# STM32H5F5xx register map
File version: 1.0
Registers are 32-bit, read-write, reset 0x0 unless marked. A register's access mark holds for its fields unless they carry their own. Offsets are from the block's base; [hi:lo] are bit positions; {n}, {i} and the like mark numbered series; 'fields as' and 'values as' point back to an identical list.

## ETH — Ethernet MAC
Base 0x40028000
Same registers: ETH_S 0x50028000
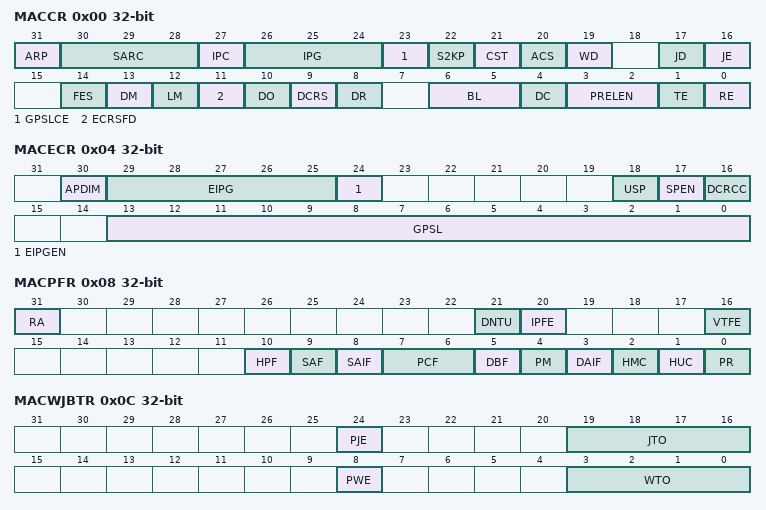
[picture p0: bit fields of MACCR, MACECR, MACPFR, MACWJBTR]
0x00 MACCR
  [31] ARP, [30:28] SARC, [27] IPC, [26:24] IPG, [23] GPSLCE, [22] S2KP, [21] CST, [20] ACS, [19] WD, [17] JD, [16] JE, [14] FES, [13] DM, [12] LM, [11] ECRSFD, [10] DO, [9] DCRS, [8] DR, [6:5] BL, [4] DC, [3:2] PRELEN, [1] TE, [0] RE
0x04 MACECR
  [30] APDIM, [29:25] EIPG, [24] EIPGEN, [18] USP, [17] SPEN, [16] DCRCC, [13:0] GPSL
0x08 MACPFR
  [31] RA, [21] DNTU, [20] IPFE, [16] VTFE, [10] HPF, [9] SAF, [8] SAIF, [7:6] PCF, [5] DBF, [4] PM, [3] DAIF, [2] HMC, [1] HUC, [0] PR
0x0C MACWJBTR
  [24] PJE, [19:16] JTO, [8] PWE, [3:0] WTO
0x10 MACHT0R
0x14 MACHT1R
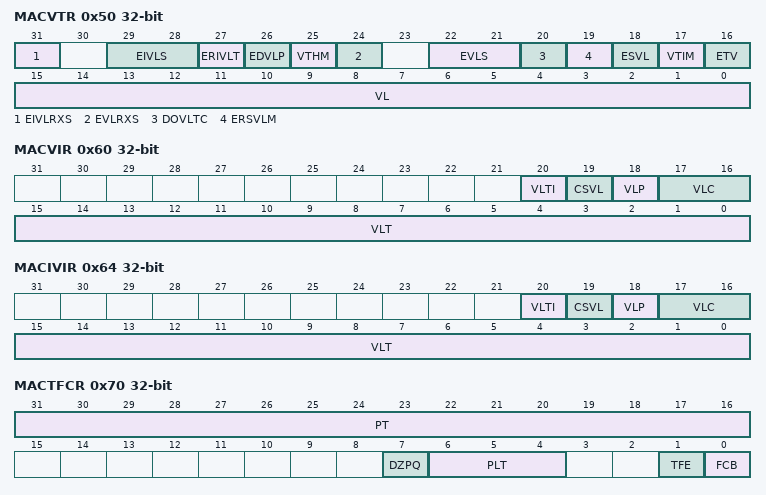
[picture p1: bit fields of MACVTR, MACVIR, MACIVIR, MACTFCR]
0x50 MACVTR
  [31] EIVLRXS, [29:28] EIVLS, [27] ERIVLT, [26] EDVLP, [25] VTHM, [24] EVLRXS, [22:21] EVLS, [20] DOVLTC, [19] ERSVLM, [18] ESVL, [17] VTIM, [16] ETV, [15:0] VL
0x58 MACVHTR
  [15:0] VLHT
0x60 MACVIR
  [20] VLTI, [19] CSVL, [18] VLP, [17:16] VLC, [15:0] VLT
0x64 MACIVIR
  [20] VLTI, [19] CSVL, [18] VLP, [17:16] VLC, [15:0] VLT
0x70 MACTFCR
  [31:16] PT, [7] DZPQ, [6:4] PLT, [1] TFE, [0] FCB
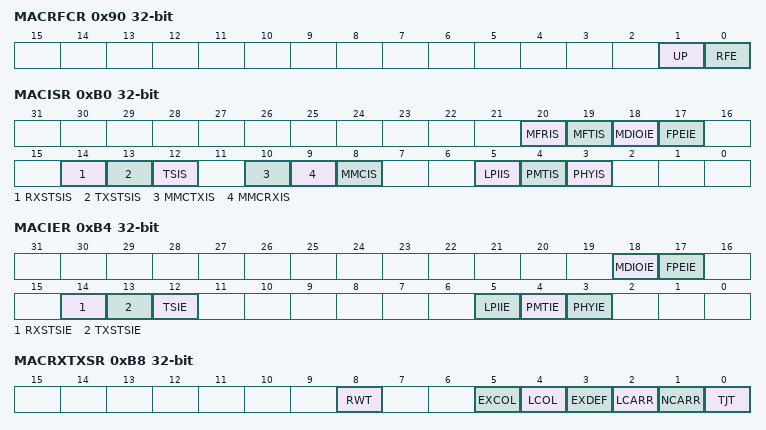
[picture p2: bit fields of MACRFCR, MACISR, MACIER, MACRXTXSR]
0x90 MACRFCR
  [1] UP, [0] RFE
0xB0 MACISR
  [20] MFRIS, [19] MFTIS, [18] MDIOIE, [17] FPEIE, [14] RXSTSIS, [13] TXSTSIS, [12] TSIS, [10] MMCTXIS, [9] MMCRXIS, [8] MMCIS, [5] LPIIS, [4] PMTIS, [3] PHYIS
0xB4 MACIER
  [18] MDIOIE, [17] FPEIE, [14] RXSTSIE, [13] TXSTSIE, [12] TSIE, [5] LPIIE, [4] PMTIE, [3] PHYIE
0xB8 MACRXTXSR
  [8] RWT, [5] EXCOL, [4] LCOL, [3] EXDEF, [2] LCARR, [1] NCARR, [0] TJT
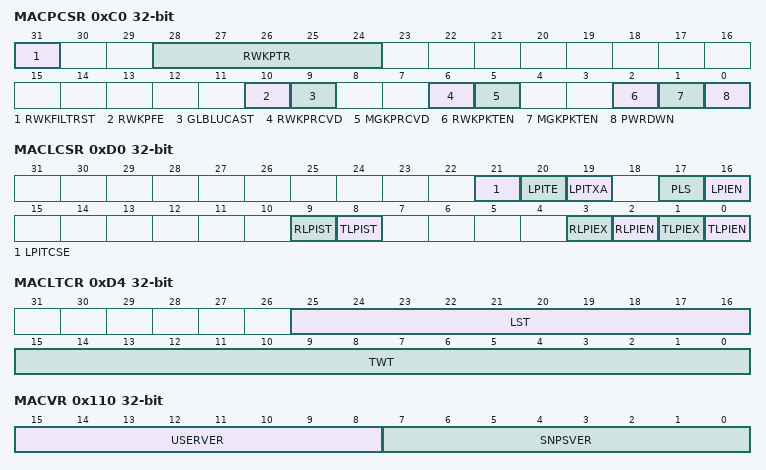
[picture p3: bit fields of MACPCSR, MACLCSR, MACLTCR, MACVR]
0xC0 MACPCSR
  [31] RWKFILTRST, [28:24] RWKPTR, [10] RWKPFE, [9] GLBLUCAST, [6] RWKPRCVD, [5] MGKPRCVD, [2] RWKPKTEN, [1] MGKPKTEN, [0] PWRDWN
0xC4 MACRWKPFR
0xD0 MACLCSR
  [21] LPITCSE, [20] LPITE, [19] LPITXA, [17] PLS, [16] LPIEN, [9] RLPIST, [8] TLPIST, [3] RLPIEX, [2] RLPIEN, [1] TLPIEX, [0] TLPIEN
0xD4 MACLTCR
  [25:16] LST, [15:0] TWT
0xD8 MACLETR
  [19:0] LPIET
0xDC MAC1USTCR
  [11:0] TIC1USCNTR
0x110 MACVR
  [15:8] USERVER, [7:0] SNPSVER
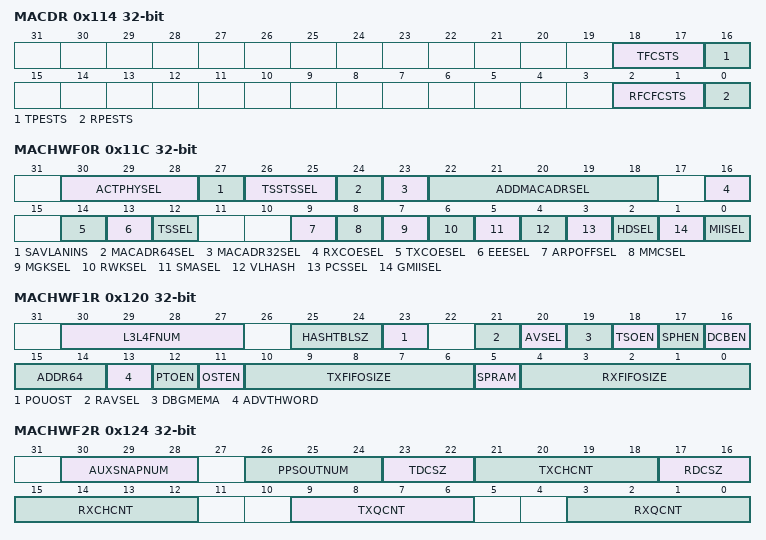
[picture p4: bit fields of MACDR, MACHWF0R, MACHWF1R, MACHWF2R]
0x114 MACDR
  [18:17] TFCSTS, [16] TPESTS, [2:1] RFCFCSTS, [0] RPESTS
0x11C MACHWF0R
  [30:28] ACTPHYSEL, [27] SAVLANINS, [26:25] TSSTSSEL, [24] MACADR64SEL, [23] MACADR32SEL, [22:18] ADDMACADRSEL, [16] RXCOESEL, [14] TXCOESEL, [13] EEESEL, [12] TSSEL, [9] ARPOFFSEL, [8] MMCSEL, [7] MGKSEL, [6] RWKSEL, [5] SMASEL, [4] VLHASH, [3] PCSSEL, [2] HDSEL, [1] GMIISEL, [0] MIISEL
0x120 MACHWF1R
  [30:27] L3L4FNUM, [25:24] HASHTBLSZ, [23] POUOST, [21] RAVSEL, [20] AVSEL, [19] DBGMEMA, [18] TSOEN, [17] SPHEN, [16] DCBEN, [15:14] ADDR64, [13] ADVTHWORD, [12] PTOEN, [11] OSTEN, [10:6] TXFIFOSIZE, [5] SPRAM, [4:0] RXFIFOSIZE
0x124 MACHWF2R
  [30:28] AUXSNAPNUM, [26:24] PPSOUTNUM, [23:22] TDCSZ, [21:18] TXCHCNT, [17:16] RDCSZ, [15:12] RXCHCNT, [9:6] TXQCNT, [3:0] RXQCNT
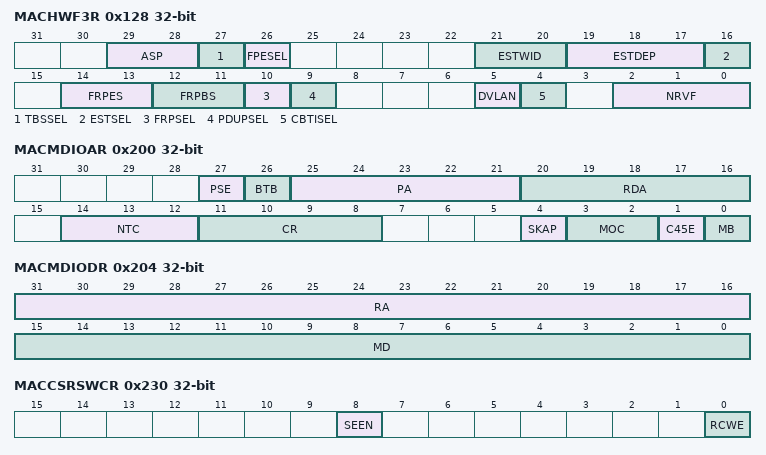
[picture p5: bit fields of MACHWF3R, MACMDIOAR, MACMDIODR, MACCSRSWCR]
0x128 MACHWF3R
  [29:28] ASP, [27] TBSSEL, [26] FPESEL, [21:20] ESTWID, [19:17] ESTDEP, [16] ESTSEL, [14:13] FRPES, [12:11] FRPBS, [10] FRPSEL, [9] PDUPSEL, [5] DVLAN, [4] CBTISEL, [2:0] NRVF
0x200 MACMDIOAR
  [27] PSE, [26] BTB, [25:21] PA, [20:16] RDA, [14:12] NTC, [11:8] CR, [4] SKAP, [3:2] MOC, [1] C45E, [0] MB
0x204 MACMDIODR
  [31:16] RA, [15:0] MD
0x210 MACARPAR
  [31:0] ARPPA
0x230 MACCSRSWCR
  [8] SEEN, [0] RCWE
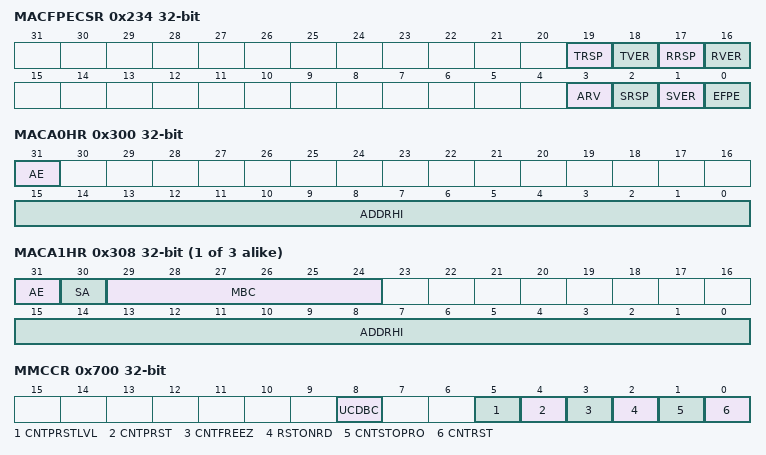
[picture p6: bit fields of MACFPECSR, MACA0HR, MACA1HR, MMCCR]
0x234 MACFPECSR
  [19] TRSP, [18] TVER, [17] RRSP, [16] RVER, [3] ARV, [2] SRSP, [1] SVER, [0] EFPE
0x240 MACPRSTIMR
  [31:0] MPTN
0x244 MACPRSTIMUR
  [31:0] MPTU
0x300 MACA0HR
  [31] AE, [15:0] ADDRHI
{0x304+8i} MACA{i}LR (i=0..3)
  [31:0] ADDRLO
{0x300+8i} MACA{i}HR (i=1..3)
  [31] AE, [30] SA, [29:24] MBC, [15:0] ADDRHI
0x700 MMCCR
  [8] UCDBC, [5] CNTPRSTLVL, [4] CNTPRST, [3] CNTFREEZ, [2] RSTONRD, [1] CNTSTOPRO, [0] CNTRST
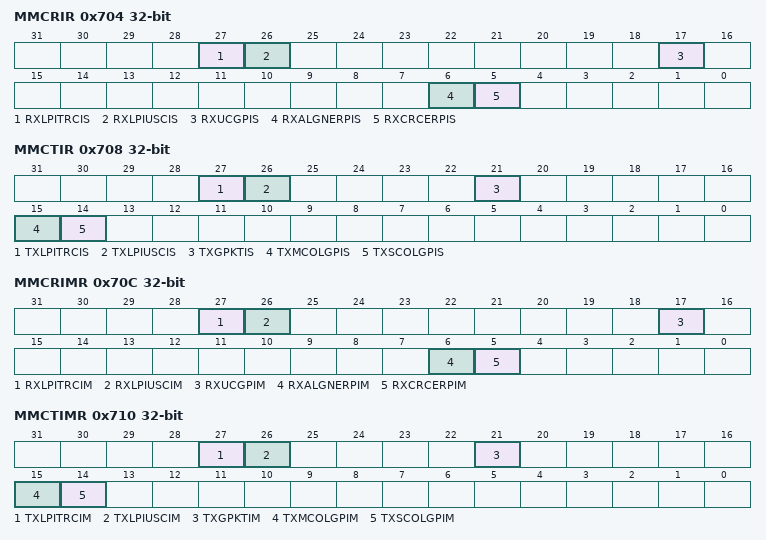
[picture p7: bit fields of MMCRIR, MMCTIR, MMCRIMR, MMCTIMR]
0x704 MMCRIR
  [27] RXLPITRCIS, [26] RXLPIUSCIS, [17] RXUCGPIS, [6] RXALGNERPIS, [5] RXCRCERPIS
0x708 MMCTIR
  [27] TXLPITRCIS, [26] TXLPIUSCIS, [21] TXGPKTIS, [15] TXMCOLGPIS, [14] TXSCOLGPIS
0x70C MMCRIMR
  [27] RXLPITRCIM, [26] RXLPIUSCIM, [17] RXUCGPIM, [6] RXALGNERPIM, [5] RXCRCERPIM
0x710 MMCTIMR
  [27] TXLPITRCIM, [26] TXLPIUSCIM, [21] TXGPKTIM, [15] TXMCOLGPIM, [14] TXSCOLGPIM
0x74C MMCTSCGPR
0x750 MMCTMCGPR
0x768 MMCTPCGR
0x794 MMCRCRCEPR
0x798 MMCRAEPR
0x7C4 MMCRUPGR
0x7EC MMCTLPIMSTR
0x7F0 MMCTLPITCR
0x7F4 MMCRLPIMSTR
0x7F8 MMCRLPITCR
0x8A0 MMCFPETISR
0x8A4 MMCFPETIMR
0x8A8 MMCFPETFCR
0x8AC MMCTHRCR
0x8C0 MMCFPERISR
0x8C4 MMCFPERIMR
0x8C8 MMCRPAER
0x8CC MMCRPSMDER
0x8D0 MMCRPAOKR
0x8D4 MMCFPERFCR
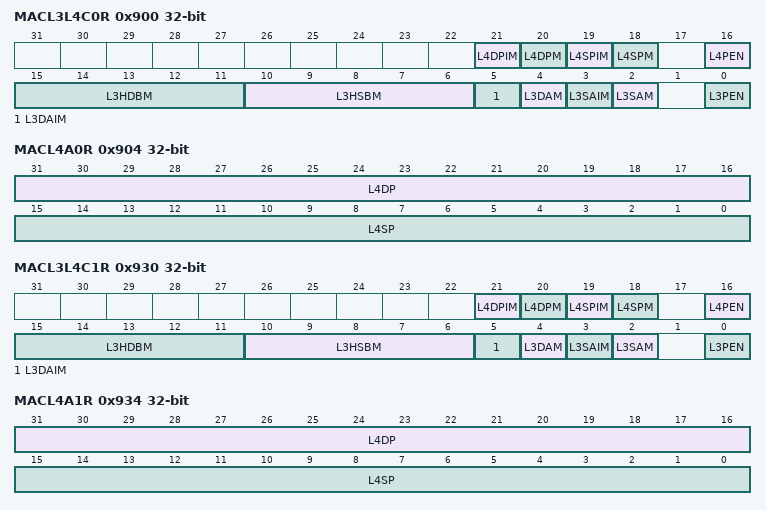
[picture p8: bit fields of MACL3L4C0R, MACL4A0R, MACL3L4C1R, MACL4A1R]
0x900 MACL3L4C0R
  [21] L4DPIM, [20] L4DPM, [19] L4SPIM, [18] L4SPM, [16] L4PEN, [15:11] L3HDBM, [10:6] L3HSBM, [5] L3DAIM, [4] L3DAM, [3] L3SAIM, [2] L3SAM, [0] L3PEN
0x904 MACL4A0R
  [31:16] L4DP, [15:0] L4SP
{0x910+4i} MACL3A{i}R0R (i=0..3)
  [31:0] L3A{i}
0x930 MACL3L4C1R
  fields as MACL3L4C0R
0x934 MACL4A1R
  [31:16] L4DP, [15:0] L4SP
{0x940+4i} MACL3A{i}R1R (i=0..3)
  [31:0] L3A{i}
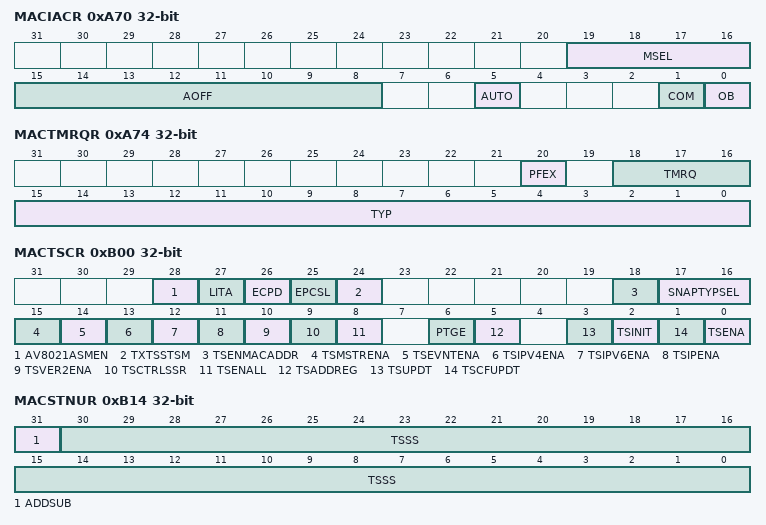
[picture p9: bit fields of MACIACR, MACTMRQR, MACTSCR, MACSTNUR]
0xA70 MACIACR
  [19:16] MSEL, [15:8] AOFF, [5] AUTO, [1] COM, [0] OB
0xA74 MACTMRQR
  [20] PFEX, [18:16] TMRQ, [15:0] TYP
0xB00 MACTSCR
  [28] AV8021ASMEN, [27] LITA, [26] ECPD, [25] EPCSL, [24] TXTSSTSM, [18] TSENMACADDR, [17:16] SNAPTYPSEL, [15] TSMSTRENA, [14] TSEVNTENA, [13] TSIPV4ENA, [12] TSIPV6ENA, [11] TSIPENA, [10] TSVER2ENA, [9] TSCTRLSSR, [8] TSENALL, [6] PTGE, [5] TSADDREG, [3] TSUPDT, [2] TSINIT, [1] TSCFUPDT, [0] TSENA
0xB04 MACSSIR
0xB08 MACSTSR
  [31:0] TSS
0xB0C MACSTNR
  [30:0] TSSS
0xB10 MACSTSUR
  [31:0] TSS
0xB14 MACSTNUR
  [31] ADDSUB, [30:0] TSSS
0xB18 MACTSAR
  [31:0] TSAR
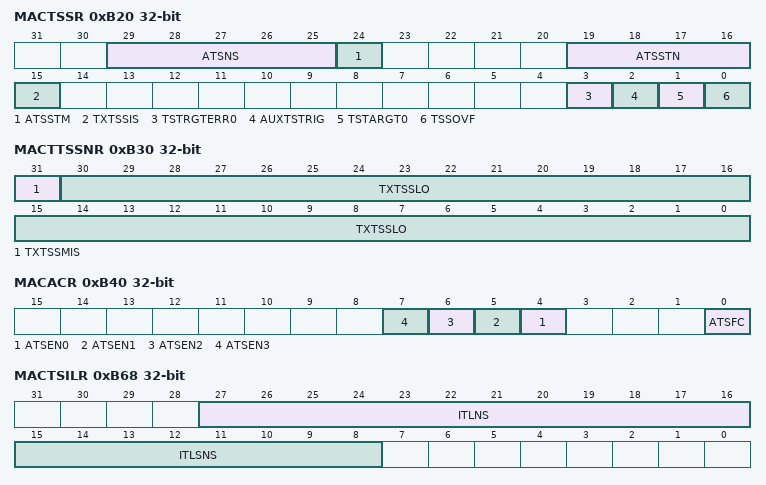
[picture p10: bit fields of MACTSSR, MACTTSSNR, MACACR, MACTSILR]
0xB20 MACTSSR
  [29:25] ATSNS, [24] ATSSTM, [19:16] ATSSTN, [15] TXTSSIS, [3] TSTRGTERR0, [2] AUXTSTRIG, [1] TSTARGT0, [0] TSSOVF
0xB24 MACRXDTI
  [31:16] RXNS
0xB28 MACTXDTI
  [31:16] TXNS
0xB30 MACTTSSNR
  [31] TXTSSMIS, [30:0] TXTSSLO
0xB34 MACTTSSSR
  [31:0] TXTSSHI
0xB40 MACACR
  [n+4] ATSEN{n} (n=0..3), [0] ATSFC
0xB48 MACATSNR
  [30:0] AUXTSLO
0xB4C MACATSSR
  [31:0] AUXTSHI
0xB50 MACTSIACR
  [31:0] OSTIAC
0xB54 MACTSEACR
  [31:0] OSTEAC
0xB58 MACTSICNR
  [31:0] TSIC
0xB5C MACTSECNR
  [31:0] TSEC
0xB68 MACTSILR
  [27:16] ITLNS, [15:8] ITLSNS
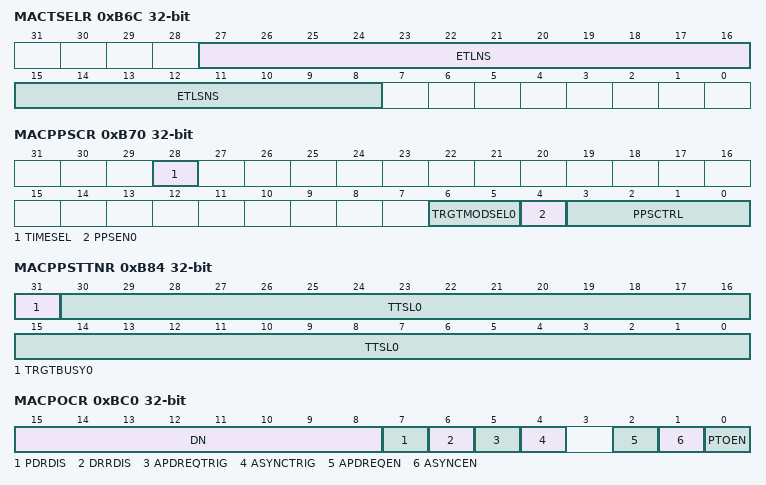
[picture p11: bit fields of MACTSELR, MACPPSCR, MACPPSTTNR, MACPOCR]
0xB6C MACTSELR
  [27:16] ETLNS, [15:8] ETLSNS
0xB70 MACPPSCR
  [28] TIMESEL, [6:5] TRGTMODSEL0, [4] PPSEN0, [3:0] PPSCTRL
0xB80 MACPPSTTSR
  [31:0] TSTRH0
0xB84 MACPPSTTNR
  [31] TRGTBUSY0, [30:0] TTSL0
0xB88 MACPPSIR
  [31:0] PPSINT0
0xB8C MACPPSWR
  [31:0] PPSWIDTH0
0xBC0 MACPOCR
  [15:8] DN, [7] PDRDIS, [6] DRRDIS, [5] APDREQTRIG, [4] ASYNCTRIG, [2] APDREQEN, [1] ASYNCEN, [0] PTOEN
0xBC4 MACSPI0R
  [31:0] SPI0
0xBC8 MACSPI1R
  [31:0] SPI1
0xBCC MACSPI2R
  [15:0] SPI2
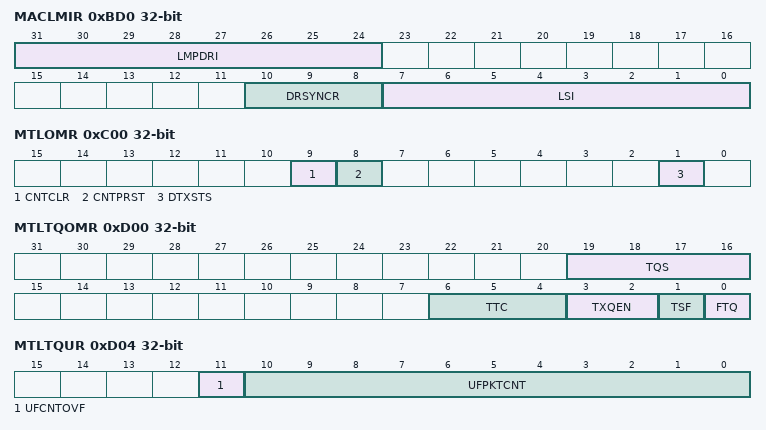
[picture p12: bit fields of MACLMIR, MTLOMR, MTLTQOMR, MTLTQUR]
0xBD0 MACLMIR
  [31:24] LMPDRI, [10:8] DRSYNCR, [7:0] LSI
0xC00 MTLOMR
  [9] CNTCLR, [8] CNTPRST, [1] DTXSTS
0xC20 MTLISR
  [0] Q0IS
0xD00 MTLTQOMR
  [19:16] TQS, [6:4] TTC, [3:2] TXQEN, [1] TSF, [0] FTQ
0xD04 MTLTQUR
  [11] UFCNTOVF, [10:0] UFPKTCNT
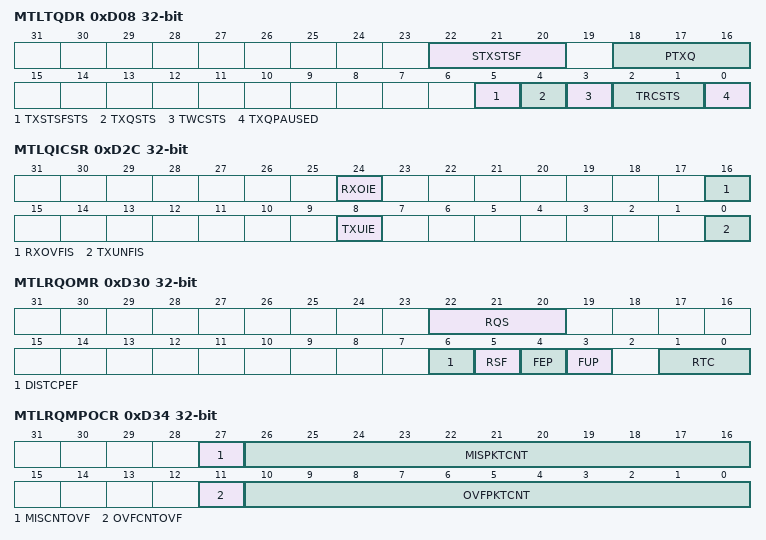
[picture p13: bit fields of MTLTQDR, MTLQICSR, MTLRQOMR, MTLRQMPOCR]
0xD08 MTLTQDR
  [22:20] STXSTSF, [18:16] PTXQ, [5] TXSTSFSTS, [4] TXQSTS, [3] TWCSTS, [2:1] TRCSTS, [0] TXQPAUSED
0xD2C MTLQICSR
  [24] RXOIE, [16] RXOVFIS, [8] TXUIE, [0] TXUNFIS
0xD30 MTLRQOMR
  [22:20] RQS, [6] DISTCPEF, [5] RSF, [4] FEP, [3] FUP, [1:0] RTC
0xD34 MTLRQMPOCR
  [27] MISCNTOVF, [26:16] MISPKTCNT, [11] OVFCNTOVF, [10:0] OVFPKTCNT
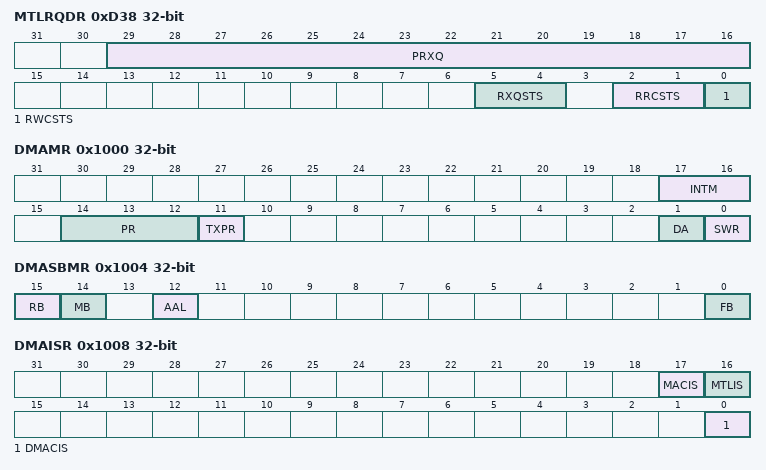
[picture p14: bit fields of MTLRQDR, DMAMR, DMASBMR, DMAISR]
0xD38 MTLRQDR
  [29:16] PRXQ, [5:4] RXQSTS, [2:1] RRCSTS, [0] RWCSTS
0x1000 DMAMR
  [17:16] INTM, [14:12] PR, [11] TXPR, [1] DA, [0] SWR
0x1004 DMASBMR
  [15] RB, [14] MB, [12] AAL, [0] FB
0x1008 DMAISR
  [17] MACIS, [16] MTLIS, [0] DMACIS
0x100C DMADSR
  [15:12] TPS, [11:8] RPS, [0] AXWHSTS
0x1100 DMACCR
  [26] DRO, [20:18] DSL, [13:0] MSS
0x1104 DMACTCR
  [21:16] TPBL, [12] TSE, [4] OSP, [0] ST
0x1108 DMACRCR
  [31] RPF, [21:16] RPBL, [14:1] RBSZ, [0] SR
0x1114 DMACTDLAR
  [31:0] TDESLA
0x111C DMACRDLAR
  [31:0] RDESLA
0x1120 DMACTDTPR
  [31:0] TDT
0x1128 DMACRDTPR
  [31:0] RDT
0x112C DMACTDRLR
  [9:0] TDRL
0x1130 DMACRDRLR
  [23:16] ARBS, [9:0] RDRL
0x1134 DMACIER
  [15] NIE, [14] AIE, [13] CDEE, [12] FBEE, [11] ERIE, [10] ETIE, [9] RWTE, [8] RSE, [7] RBUE, [6] RIE, [2] TBUE, [1] TXSE, [0] TIE
0x1138 DMACRIWTR
  [31] PSEL, [29:20] RBCT, [19:18] ITCU, [17:16] RWTU, [12:8] ITW, [7:0] RWT
0x1144 DMACCATDR
  [31:0] CURTDESAPTR
0x114C DMACCARDR
  [31:0] CURRDESAPTR
0x1154 DMACCATBR
  [31:0] CURTBUFAPTR
0x115C DMACCARBR
  [31:0] CURRBUFAPTR
0x1160 DMACSR
  [21:19] REB, [18:16] TEB, [15] NIS, [14] AIS, [13] CDE, [12] FBE, [11] ERI, [10] ETI, [9] RWT, [8] RPS, [7] RBU, [6] RI, [2] TBU, [1] TPS, [0] TI
0x1164 DMACMFCR
  [15] MFCO, [10:0] MFC
